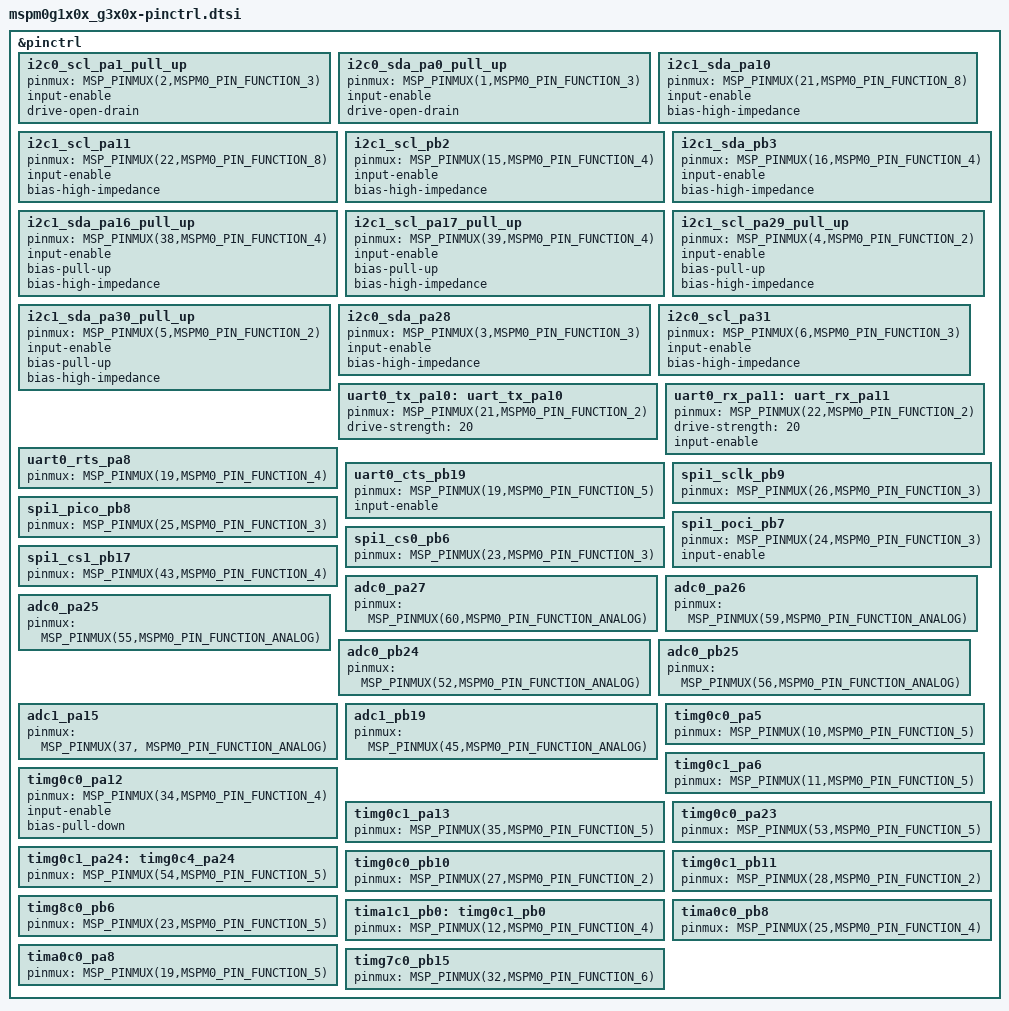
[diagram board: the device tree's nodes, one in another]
#include <dt-bindings/pinctrl/mspm0-pinctrl.h>

&pinctrl {

	/omit-if-no-ref/ i2c0_scl_pa1_pull_up: i2c0_scl_pa1_pull_up {
		pinmux = <MSP_PINMUX(2,MSPM0_PIN_FUNCTION_3)>;
		input-enable;
		drive-open-drain;
	};

	/omit-if-no-ref/ i2c0_sda_pa0_pull_up: i2c0_sda_pa0_pull_up {
		pinmux = <MSP_PINMUX(1,MSPM0_PIN_FUNCTION_3)>;
		input-enable;
		drive-open-drain;
	};

	/omit-if-no-ref/ i2c1_sda_pa10: i2c1_sda_pa10 {
		pinmux = <MSP_PINMUX(21,MSPM0_PIN_FUNCTION_8)>;
		input-enable;
		bias-high-impedance;
	};

	/omit-if-no-ref/ i2c1_scl_pa11: i2c1_scl_pa11 {
		pinmux = <MSP_PINMUX(22,MSPM0_PIN_FUNCTION_8)>;
		input-enable;
		bias-high-impedance;
	};

	/omit-if-no-ref/ i2c1_scl_pb2: i2c1_scl_pb2 {
		pinmux = <MSP_PINMUX(15,MSPM0_PIN_FUNCTION_4)>;
		input-enable;
		bias-high-impedance;
	};

	/omit-if-no-ref/ i2c1_sda_pb3: i2c1_sda_pb3 {
		pinmux = <MSP_PINMUX(16,MSPM0_PIN_FUNCTION_4)>;
		input-enable;
		bias-high-impedance;
	};

	/omit-if-no-ref/ i2c1_sda_pa16_pull_up: i2c1_sda_pa16_pull_up {
		pinmux = <MSP_PINMUX(38,MSPM0_PIN_FUNCTION_4)>;
		input-enable;
		bias-pull-up;
		bias-high-impedance;
	};

	/omit-if-no-ref/ i2c1_scl_pa17_pull_up: i2c1_scl_pa17_pull_up {
		pinmux = <MSP_PINMUX(39,MSPM0_PIN_FUNCTION_4)>;
		input-enable;
		bias-pull-up;
		bias-high-impedance;
	};

	/omit-if-no-ref/ i2c1_scl_pa29_pull_up: i2c1_scl_pa29_pull_up {
		pinmux = <MSP_PINMUX(4,MSPM0_PIN_FUNCTION_2)>;
		input-enable;
		bias-pull-up;
		bias-high-impedance;
	};

	/omit-if-no-ref/ i2c1_sda_pa30_pull_up: i2c1_sda_pa30_pull_up {
		pinmux = <MSP_PINMUX(5,MSPM0_PIN_FUNCTION_2)>;
		input-enable;
		bias-pull-up;
		bias-high-impedance;
	};

	/omit-if-no-ref/ i2c0_sda_pa28: i2c0_sda_pa28 {
		pinmux = <MSP_PINMUX(3,MSPM0_PIN_FUNCTION_3)>;
		input-enable;
		bias-high-impedance;
	};

	/omit-if-no-ref/ i2c0_scl_pa31: i2c0_scl_pa31 {
		pinmux = <MSP_PINMUX(6,MSPM0_PIN_FUNCTION_3)>;
		input-enable;
		bias-high-impedance;
	};

	/omit-if-no-ref/ uart0_tx_pa10: uart_tx_pa10 {
		pinmux = <MSP_PINMUX(21,MSPM0_PIN_FUNCTION_2)>;
		drive-strength = <20>;
	};

	/omit-if-no-ref/ uart0_rx_pa11: uart_rx_pa11 {
		pinmux = <MSP_PINMUX(22,MSPM0_PIN_FUNCTION_2)>;
		drive-strength = <20>;
		input-enable;
	};

	/omit-if-no-ref/ uart0_rts_pa8: uart0_rts_pa8 {
		pinmux = <MSP_PINMUX(19,MSPM0_PIN_FUNCTION_4)>;
	};

	/omit-if-no-ref/ uart0_cts_pb19: uart0_cts_pb19 {
		pinmux = <MSP_PINMUX(19,MSPM0_PIN_FUNCTION_5)>;
		input-enable;
	};

	/omit-if-no-ref/ spi1_sclk_pb9: spi1_sclk_pb9 {
		pinmux = <MSP_PINMUX(26,MSPM0_PIN_FUNCTION_3)>;
	};

	/omit-if-no-ref/ spi1_pico_pb8: spi1_pico_pb8 {
		pinmux = <MSP_PINMUX(25,MSPM0_PIN_FUNCTION_3)>;
	};

	/omit-if-no-ref/ spi1_poci_pb7: spi1_poci_pb7 {
		pinmux = <MSP_PINMUX(24,MSPM0_PIN_FUNCTION_3)>;
		input-enable;
	};

	/omit-if-no-ref/ spi1_cs0_pb6: spi1_cs0_pb6 {
		pinmux = <MSP_PINMUX(23,MSPM0_PIN_FUNCTION_3)>;
	};

	/omit-if-no-ref/ spi1_cs1_pb17: spi1_cs1_pb17 {
		pinmux = <MSP_PINMUX(43,MSPM0_PIN_FUNCTION_4)>;
	};

	/omit-if-no-ref/ adc0_pa27: adc0_pa27 {
		pinmux = <MSP_PINMUX(60,MSPM0_PIN_FUNCTION_ANALOG)>;
	};

	/omit-if-no-ref/ adc0_pa26: adc0_pa26 {
		pinmux = <MSP_PINMUX(59,MSPM0_PIN_FUNCTION_ANALOG)>;
	};

	/omit-if-no-ref/ adc0_pa25: adc0_pa25 {
		pinmux = <MSP_PINMUX(55,MSPM0_PIN_FUNCTION_ANALOG)>;
	};

	/omit-if-no-ref/ adc0_pb24: adc0_pb24 {
		pinmux = <MSP_PINMUX(52,MSPM0_PIN_FUNCTION_ANALOG)>;
	};

	/omit-if-no-ref/ adc0_pb25: adc0_pb25 {
		pinmux = <MSP_PINMUX(56,MSPM0_PIN_FUNCTION_ANALOG)>;
	};

	/omit-if-no-ref/ adc1_pa15: adc1_pa15 {
		pinmux = <MSP_PINMUX(37, MSPM0_PIN_FUNCTION_ANALOG)>;
	};

	/omit-if-no-ref/ adc1_pb19: adc1_pb19 {
		pinmux = <MSP_PINMUX(45,MSPM0_PIN_FUNCTION_ANALOG)>;
	};

	/omit-if-no-ref/ timg0c0_pa5: timg0c0_pa5 {
		pinmux = <MSP_PINMUX(10,MSPM0_PIN_FUNCTION_5)>;
	};

	/omit-if-no-ref/ timg0c1_pa6: timg0c1_pa6 {
		pinmux = <MSP_PINMUX(11,MSPM0_PIN_FUNCTION_5)>;
	};

	/omit-if-no-ref/ timg0c0_pa12: timg0c0_pa12 {
		pinmux = <MSP_PINMUX(34,MSPM0_PIN_FUNCTION_4)>;
		input-enable;
		bias-pull-down;
	};

	/omit-if-no-ref/ timg0c1_pa13: timg0c1_pa13 {
		pinmux = <MSP_PINMUX(35,MSPM0_PIN_FUNCTION_5)>;
	};

	/omit-if-no-ref/ timg0c0_pa23: timg0c0_pa23 {
		pinmux = <MSP_PINMUX(53,MSPM0_PIN_FUNCTION_5)>;
	};

	/omit-if-no-ref/ timg0c1_pa24: timg0c4_pa24 {
		pinmux = <MSP_PINMUX(54,MSPM0_PIN_FUNCTION_5)>;
	};

	/omit-if-no-ref/ timg0c0_pb10: timg0c0_pb10 {
		pinmux = <MSP_PINMUX(27,MSPM0_PIN_FUNCTION_2)>;
	};

	/omit-if-no-ref/ timg0c1_pb11: timg0c1_pb11 {
		pinmux = <MSP_PINMUX(28,MSPM0_PIN_FUNCTION_2)>;
	};

	/omit-if-no-ref/ timg8c0_pb6: timg8c0_pb6 {
		pinmux = <MSP_PINMUX(23,MSPM0_PIN_FUNCTION_5)>;
	};

	/omit-if-no-ref/ tima1c1_pb0: timg0c1_pb0 {
		pinmux = <MSP_PINMUX(12,MSPM0_PIN_FUNCTION_4)>;
	};

	/omit-if-no-ref/ tima0c0_pb8: tima0c0_pb8 {
		pinmux = <MSP_PINMUX(25,MSPM0_PIN_FUNCTION_4)>;
	};

	/omit-if-no-ref/ tima0c0_pa8: tima0c0_pa8{
		pinmux = <MSP_PINMUX(19,MSPM0_PIN_FUNCTION_5)>;
	};

	/omit-if-no-ref/ timg7c0_pb15: timg7c0_pb15{
		pinmux = <MSP_PINMUX(32,MSPM0_PIN_FUNCTION_6)>;
	};
};
